# aif2 register map
Vendor: Texas Instruments
Registers are 32-bit, read-write, no defined reset value unless marked. A register's access mark holds for its fields unless they carry their own. Offsets are as the file gives them; [hi:lo] are bit positions; {n}, {i} and the like mark numbered series; 'fields as' and 'values as' point back to an identical list.

## AIF2 (part 2 of 3)
0xE010 AD_Ingress_Scheduler_EOP_Counter_Register ro — This register provides a count of the EOPs sent to the CPPI DMA Controller for activity monitoring.
  [23:0] eop_cnt — Wrapping count of EOPs sent to the CPPI DMA COntroller.
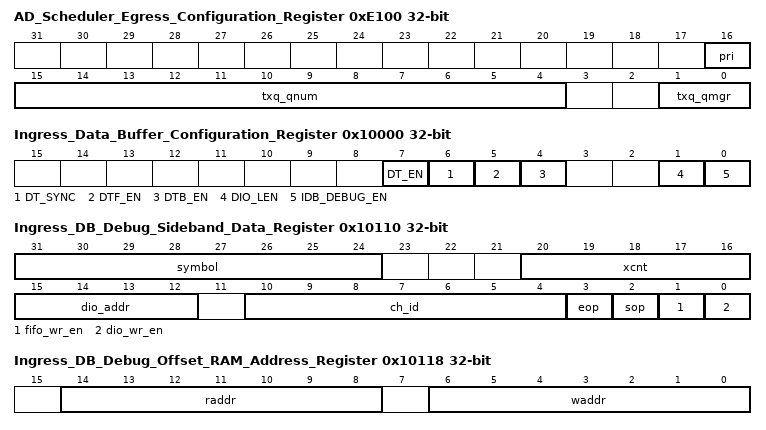
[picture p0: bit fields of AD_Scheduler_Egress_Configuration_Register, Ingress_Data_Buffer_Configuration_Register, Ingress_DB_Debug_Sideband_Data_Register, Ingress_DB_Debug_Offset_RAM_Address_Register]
0xE100 AD_Scheduler_Egress_Configuration_Register
  [16] pri — This field controls the Egress Scheduler aribitration priority
  [15:4] txq_qnum — Base egress queue number for AIF2. Channel id of each packet 127-0 added to this base value to generate egress queue number sent to CDMA Scheduling Interface. 0xF80 to 0x000
  [1:0] txq_qmgr — Queue manager number sent to CDMA Scheduling Interface for all egress transactions 0x3 to 0x0
0xE104 AD_Scheduler_Egress_Global_Enable_Set_Register wo — Set Global Enable for AD Egress Scheduler
  [31:0] DONT_CARE — A write of any value to this register sets the global enable for the AD Egress Scheduler
0xE108 AD_Scheduler_Egress_Global_Enable_Clear wo — Clear Global Enable for AD Egress Scheduler
  [31:0] DONT_CARE — A write of any value to this register clears the global enable for the AD Egress Scheduler
0xE10C AD_Scheduler_Egress_Global_Enable_Status ro — Read Only status of AD Egress Scheduler global enable state.
  [0] ENABLE — 0x1: AD Egress Scheduler_ON 0x0:AD Egress Scheduler OFF
0x10000 Ingress_Data_Buffer_Configuration_Register
  [7] DT_EN — Data Trace Enable
  [6] DT_SYNC — Data Trace Sync Enable. When data trace capture is synchronized to the frame boundary, the least significant byte of the first quad-word is always the first byte of the frame regardless of whether the first byte was the even or odd byte
  [5] DTF_EN — Trace Framing Data Capture Enable
  [4] DTB_EN — Trace Data Capture Enable
  [1] DIO_LEN — DirectIO buffer length
  [0] IDB_DEBUG_EN — Enable Ingress DB debug mode
0x10004 IDB_Global_Enable_Set_Register wo — Set Global Enable for Ingress DB
  [31:0] DONT_CARE — A write of any value to this register sets the global enable for the Ingress DB
0x10008 IDB_Global_Enable_Clear_Register wo — Clear Global Enable for Ingress DB
  [31:0] DONT_CARE — A write of any value to this register clears the global enable for the Ingress DB
0x1000C IDB_Global_Enable_Status_Register ro — Read Only status of Ingress DB global enable state.
  [0] ENABLE — 0x1: Ingress DB_ON 0x0:Ingress DB OFF
0x10010 Ingress_Data_Buffer_Channel_Enable_Register — (1 of 4, stride 4)
  [31:0] EN — Each bit is an enable for 1 of 32 contiguous Ingress data buffer channels
{0x10100+4i} Ingress_DB_Debug_Data_Register_{i} (i=0..3)
  [31:0] DATA — Debug data written to bits {32i+31}:{32i} of Ingress DB RAM
0x10110 Ingress_DB_Debug_Sideband_Data_Register — This register provides sideband data that is written into the Ingress DB RAM during debug.
  [31:24] symbol — AxC symbol number inserted as part of protocol specific data (0x00
  [20:16] xcnt — Transfer Byte Count: Indicates how many valid bytes are transferred in the current data phase.
  [15:12] dio_addr — Address within a DirectIO Circular Buffer. Each address contains a quad-word and 16 locations support up to 256 byte circular buffers.
  [10:4] ch_id — DMA channel number 127-0
  [3] eop — End of packet
  [2] sop — Start of packet
  [1] fifo_wr_en — FIFO Buffer Write Enable
  [0] dio_wr_en — DirectIO Buffer Write Enable
0x10114 Ingress_DB_Debug_DB_Write wo — A write of any value to this register writes the data in the following registers into the Ingress DB RAM and sideband RAMS: DB_IDB_DEBUG_D0, DB_IDB_DEBUG_D1, DB_IDB_DEBUG_D2, DB_IDB_DEBUG_D3, DB_IDB_DEBUG_SBDN0, DB_IDB_DEBUG_SBDN1
  [31:0] DONT_CARE — A write of any value to this register writes the data in the following registers into the Ingress DB and sideband RAMS: DB_IDB_DEBUG_D0, DB_IDB_DEBUG_D1, DB_IDB_DEBUG_D2, DB_IDB_DEBUG_D3, DB_IDB_DEBUG_SBDN0, DB_IDB_DEBUG_SBDN1
0x10118 Ingress_DB_Debug_Offset_RAM_Address_Register — This register provides the addresses to access the Ingress read and write offset RAMs for debug.
  [14:8] raddr — Address used to access read offset RAM
  [6:0] waddr — Address used to access write offset RAM
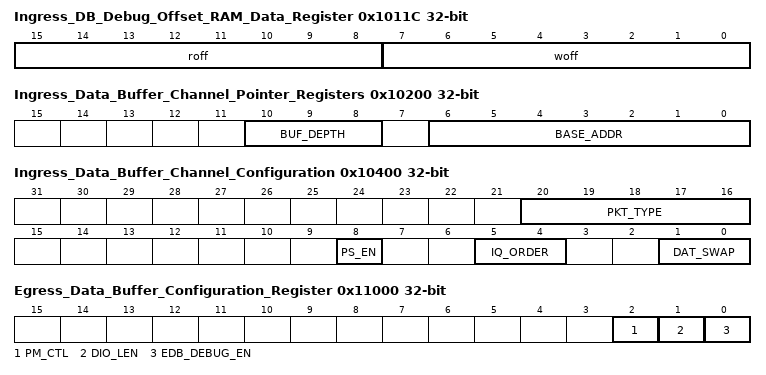
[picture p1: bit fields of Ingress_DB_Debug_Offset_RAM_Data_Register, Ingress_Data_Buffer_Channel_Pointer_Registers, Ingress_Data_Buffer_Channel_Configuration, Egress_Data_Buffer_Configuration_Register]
0x1011C Ingress_DB_Debug_Offset_RAM_Data_Register ro — This register contains the offset value read from the Ingress read and write offset RAMs for debug.
  [15:8] roff — Read offset value at address in DB_IDB_DEBUG_OFS.RADDR
  [7:0] woff — Write Offset Value at address in DB_IDB_DEBUG_OFS.WADDR
0x10200 Ingress_Data_Buffer_Channel_Pointer_Registers — (1 of 128, stride 4)
  [10:8] BUF_DEPTH — Depth of FIFO Buffer in number of quad-words (ignored for DirectIO circular buffers)
  [6:0] BASE_ADDR — Starting address of per-channel FIFO or DirectIO buffer.
0x10400 Ingress_Data_Buffer_Channel_Configuration — (1 of 128, stride 4)
  [20:16] PKT_TYPE — Programmable packet type that is inserted into pkt_type field in CPPI Info Word 0.
  [8] PS_EN — Protocol Specific Data Enable.
  [5:4] IQ_ORDER — IQ swapping scheme.
  [1:0] DAT_SWAP — Big endian swapping control.
0x10600 Ingress_Data_Buffer_Channel_Empty_Register ro — (1 of 4, stride 4)
  [31:0] EMPTY — Each bit is a buffer empty bit for 1 of 32 contiguous Ingress data buffer channels
0x11000 Egress_Data_Buffer_Configuration_Register
  [2] PM_CTL — PM Token Control
  [1] DIO_LEN — DirectIO buffer length
  [0] EDB_DEBUG_EN — Enable Egress DB debug mode
0x11004 EDB_Global_Enable_Set_Register wo — Set Global Enable for Egress DB
  [31:0] DONT_CARE — A write of any value to this register sets the global enable for the Egress DB
0x11008 EDB_Global_Enable_Clear_Register wo — Clear Global Enable for Egress DB
  [31:0] DONT_CARE — A write of any value to this register clears the global enable for the Egress DB
0x1100C EDB_Global_Enable_Status_Register ro — Read Only status of Egress DB global enable state.
  [0] ENABLE — 0x1: Egress DB_ON 0x0:Egress DB OFF
0x11010 Egress_Data_Buffer_Channel_Enable_Register — (1 of 4, stride 4)
  [31:0] EN — Each bit is an enable for 1 of 32 contiguous Egress data buffer channels
{0x11100+4i} Egress_DB_Debug_Data_Register_{i} ro (i=0..3)
  [31:0] DATA — Debug data read from bits {32i+31}:{32i} of Egress DB RAM
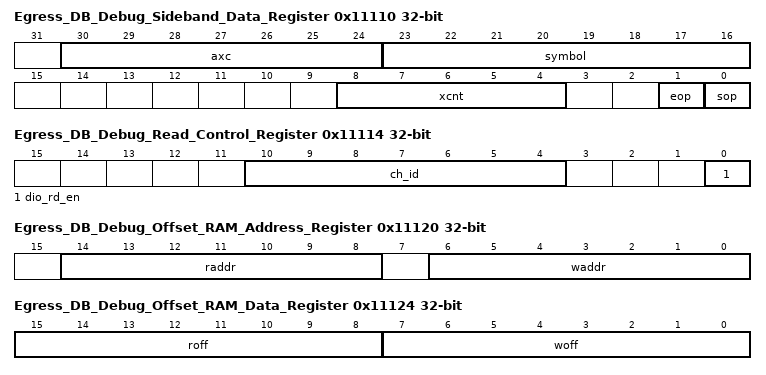
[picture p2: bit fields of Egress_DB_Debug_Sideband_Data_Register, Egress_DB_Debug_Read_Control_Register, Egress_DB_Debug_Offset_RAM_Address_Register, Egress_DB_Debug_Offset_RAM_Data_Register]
0x11110 Egress_DB_Debug_Sideband_Data_Register ro — This register provides part of the sideband data that is written into the Egress DB RAM during debug.
  [30:24] axc — AxC number from protocol specific data. Not applicable for DirectIO. For OBSAI GSM BB hopping AxC, bits \[6:0\] of OBSAI address
  [23:16] symbol — SYMBOL NUMBER from protocol specific data. Not applicable for DirectIO. For OBSAI GSM BB hopping AxC, bits \[12:7\] of OBSAI address in symbol\[5:0\]
  [8:4] xcnt — Transfer Byte Count: Indicates how many bytes in DB_EDB_DEBUG_D0, DB_EDB_DEBUG_D1, DB_EDB_DEBUG_D2, DB_EDB_DEBUG_D3 and DB_EDB_DEBUG_SBND are valid.
  [1] eop — End of packet
  [0] sop — Start of packet
0x11114 Egress_DB_Debug_Read_Control_Register — This register provides the controls necessary to read the Egress DB RAM during debug.
  [10:4] ch_id — Egress Data Buffer channel number 127-0; Also used as token channel number when DB_EDB_DEBUG_WR_TOK written
  [0] dio_rd_en — DirectIO Buffer Read Enable
0x1111C Egress_DB_Debug_DB_Read_Register wo — A write of any value to this register initiates a read to the Egress DB data and sideband RAMs and writes the contents into the following registers: DB_EDB_DEBUG_D0, DB_EDB_DEBUG_D1, DB_EDB_DEBUG_D2, DB_EDB_DEBUG_D3, DB_EDB_DEBUG_SBND
  [31:0] DONT_CARE
0x11120 Egress_DB_Debug_Offset_RAM_Address_Register — This register provides the addresses to access the Egress read and write offset RAMs for debug.
  fields as Ingress_DB_Debug_Offset_RAM_Address_Register
0x11124 Egress_DB_Debug_Offset_RAM_Data_Register ro — This register contains the offset value read from the Egress read and write offset RAMs for debug.
  [15:8] roff — Read offset value at address in DB_EDB_DEBUG_OFS.RADDR
  [7:0] woff — Write Offset Value at address in DB_EDB_DEBUG_OFS.WADDR
0x11128 Egress_DB_Debug_Write_Token_Register wo — A write of any value to this register results in a token with the value loaded into DB_EDB_DEBUG_RD_CNTL.CH_ID being issued to the AxC Token FIFO
  [31:0] DONT_CARE
0x1112C Egress_DB_EOP_Counter_Register ro — This register provides a count of the Egress EOPs received from the CPPI DMA Controller for activity monitoring.
  [23:0] eop_cnt — Wrapping count of EOPs received from the CPPI DMA COntroller.
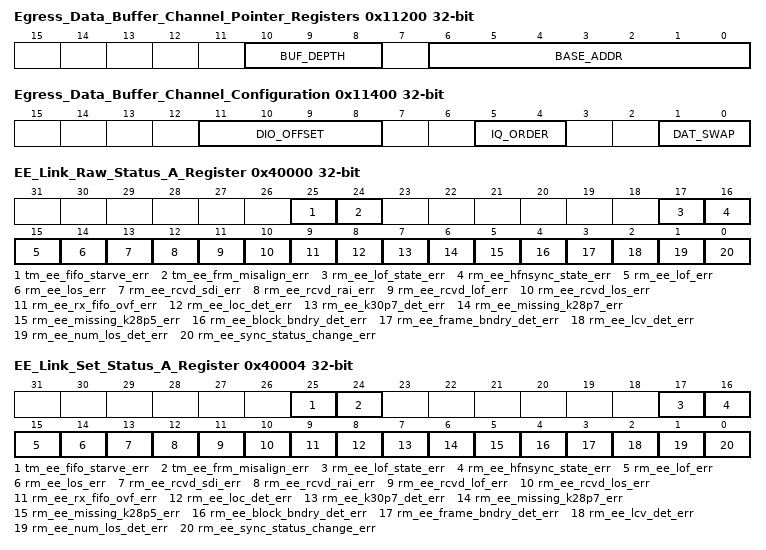
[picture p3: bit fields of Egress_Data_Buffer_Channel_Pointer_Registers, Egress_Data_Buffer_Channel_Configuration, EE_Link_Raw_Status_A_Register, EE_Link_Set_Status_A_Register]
0x11200 Egress_Data_Buffer_Channel_Pointer_Registers — (1 of 128, stride 4)
  fields as Ingress_Data_Buffer_Channel_Pointer_Registers
0x11400 Egress_Data_Buffer_Channel_Configuration — (1 of 128, stride 4)
  [11:8] DIO_OFFSET — Address offset of SOP for DIO channels
  [5:4] IQ_ORDER — IQ swapping scheme.
  [1:0] DAT_SWAP — Big endian swapping control.
0x40000 EE_Link_Raw_Status_A_Register ro — (1 of 6, stride 128)
  [25] tm_ee_fifo_starve_err — TM FIFO Strave Error.
  [24] tm_ee_frm_misalign_err — TM Frame Misalign Error.
  [17] rm_ee_lof_state_err — RM LOF State Error.
  [16] rm_ee_hfnsync_state_err — RM Hyperframe State Error.
  [15] rm_ee_lof_err — RM LOF Error
  [14] rm_ee_los_err — RM LOS Error.
  [13] rm_ee_rcvd_sdi_err — RM Received SDI Error.
  [12] rm_ee_rcvd_rai_err — RM Received RAI Error.
  [11] rm_ee_rcvd_lof_err — RM Received LOF Error.
  [10] rm_ee_rcvd_los_err — RM Received LOS Error.
  [9] rm_ee_rx_fifo_ovf_err — RM RX FIFO Overflow Error.
  [8] rm_ee_loc_det_err — RM LOC Detect Error.
  [7] rm_ee_k30p7_det_err — RM K30p7 Detect Error.
  [6] rm_ee_missing_k28p7_err — RM Missing K28p7 Error.
  [5] rm_ee_missing_k28p5_err — RM Missing K28p5 Error.
  [4] rm_ee_block_bndry_det_err — RM Block Boundary Detect Error.
  [3] rm_ee_frame_bndry_det_err — RM Frame Boundary Detect Error.
  [2] rm_ee_lcv_det_err — RM LCV Detect Error.
  [1] rm_ee_num_los_det_err — RM Num Loss Detect Error.
  [0] rm_ee_sync_status_change_err — RM Sync Status Change Error.
0x40004 EE_Link_Set_Status_A_Register wo — (1 of 6, stride 128)
  [25] tm_ee_fifo_starve_err — TM FIFO Strave Error Set.
  [24] tm_ee_frm_misalign_err — TM Frame Misalign Error Set.
  [17] rm_ee_lof_state_err — RM LOF State Error Set.
  [16] rm_ee_hfnsync_state_err — RM Hyperframe State Error Set.
  [15] rm_ee_lof_err — RM LOF Error Set.
  [14] rm_ee_los_err — RM LOS Error Set.
  [13] rm_ee_rcvd_sdi_err — RM Received SDI Error Set.
  [12] rm_ee_rcvd_rai_err — RM Received RAI Error Set.
  [11] rm_ee_rcvd_lof_err — RM Received LOF Error Set.
  [10] rm_ee_rcvd_los_err — RM Received LOS Error Set.
  [9] rm_ee_rx_fifo_ovf_err — RM RX FIFO Overflow Error Set.
  [8] rm_ee_loc_det_err — RM LOC Detect Error Set.
  [7] rm_ee_k30p7_det_err — RM K30p7 Detect Error Set.
  [6] rm_ee_missing_k28p7_err — RM Missing K28p7 Error Set.
  [5] rm_ee_missing_k28p5_err — RM Missing K28p5 Error Set.
  [4] rm_ee_block_bndry_det_err — RM Block Boundary Detect Error Set.
  [3] rm_ee_frame_bndry_det_err — RM Frame Boundary Detect Error Set.
  [2] rm_ee_lcv_det_err — RM LCV Detect Error Set.
  [1] rm_ee_num_los_det_err — RM Num Loss Detect Error Set.
  [0] rm_ee_sync_status_change_err — RM Sync Status Change Error Set.
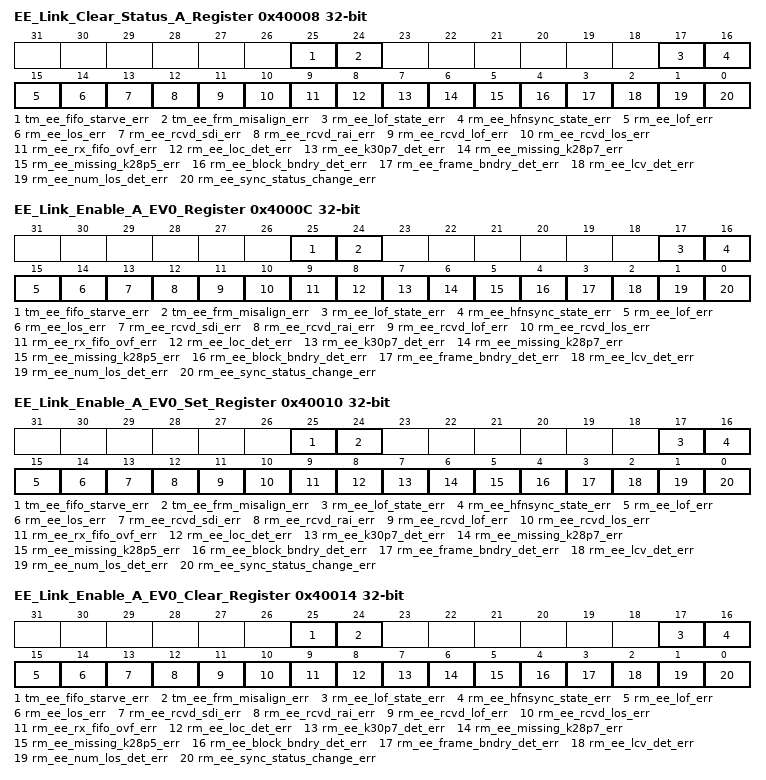
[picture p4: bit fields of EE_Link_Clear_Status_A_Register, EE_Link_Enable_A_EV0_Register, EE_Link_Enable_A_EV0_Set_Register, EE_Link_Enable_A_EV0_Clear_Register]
0x40008 EE_Link_Clear_Status_A_Register wo — (1 of 6, stride 128)
  [25] tm_ee_fifo_starve_err — TM FIFO Strave Error Clear.
  [24] tm_ee_frm_misalign_err — TM Frame Misalign Error Clear.
  [17] rm_ee_lof_state_err — RM LOF State Error Clear.
  [16] rm_ee_hfnsync_state_err — RM Hyperframe State Error Clear.
  [15] rm_ee_lof_err — RM LOF Error Clear.
  [14] rm_ee_los_err — RM LOS Error Clear.
  [13] rm_ee_rcvd_sdi_err — RM Received SDI Error Clear.
  [12] rm_ee_rcvd_rai_err — RM Received RAI Error Clear.
  [11] rm_ee_rcvd_lof_err — RM Received LOF Error Clear.
  [10] rm_ee_rcvd_los_err — RM Received LOS Error Clear.
  [9] rm_ee_rx_fifo_ovf_err — RM RX FIFO Overflow Error Clear.
  [8] rm_ee_loc_det_err — RM LOC Detect Error Clear.
  [7] rm_ee_k30p7_det_err — RM K30p7 Detect Error Clear.
  [6] rm_ee_missing_k28p7_err — RM Missing K28p7 Error Clear.
  [5] rm_ee_missing_k28p5_err — RM Missing K28p5 Error Clear.
  [4] rm_ee_block_bndry_det_err — RM Block Boundary Detect Error Clear.
  [3] rm_ee_frame_bndry_det_err — RM Frame Boundary Detect Error Clear.
  [2] rm_ee_lcv_det_err — RM LCV Detect Error Clear.
  [1] rm_ee_num_los_det_err — RM Num Loss Detect Erro Clear.
  [0] rm_ee_sync_status_change_err — RM Sync Status Change Error Clear.
0x4000C EE_Link_Enable_A_EV0_Register ro — (1 of 6, stride 128)
  [25] tm_ee_fifo_starve_err — TM FIFO Strave Error Enable.
  [24] tm_ee_frm_misalign_err — TM Frame Misalign Error Enable.
  [17] rm_ee_lof_state_err — RM LOF State Error Enable.
  [16] rm_ee_hfnsync_state_err — RM Hyperframe State Error Enable.
  [15] rm_ee_lof_err — RM LOF Error Enable.
  [14] rm_ee_los_err — RM LOS Error Enable.
  [13] rm_ee_rcvd_sdi_err — RM Received SDI Error Enable.
  [12] rm_ee_rcvd_rai_err — RM Received RAI Error Enable.
  [11] rm_ee_rcvd_lof_err — RM Received LOF Error Enable.
  [10] rm_ee_rcvd_los_err — RM Received LOS Error Enable.
  [9] rm_ee_rx_fifo_ovf_err — RM RX FIFO Overflow Error Enable.
  [8] rm_ee_loc_det_err — RM LOC Detect Error Enable.
  [7] rm_ee_k30p7_det_err — RM K30p7 Detect Error Enable.
  [6] rm_ee_missing_k28p7_err — RM Missing K28p7 Error Enable.
  [5] rm_ee_missing_k28p5_err — RM Missing K28p5 Error Enable.
  [4] rm_ee_block_bndry_det_err — RM Block Boundary Detect Error Enable.
  [3] rm_ee_frame_bndry_det_err — RM Frame Boundary Detect Error Enable.
  [2] rm_ee_lcv_det_err — RM LCV Detect Error Enable.
  [1] rm_ee_num_los_det_err — RM Num Loss Detect ErroSet.
  [0] rm_ee_sync_status_change_err — RM Sync Status Change Error Enable.
0x40010 EE_Link_Enable_A_EV0_Set_Register wo — (1 of 6, stride 128)
  [25] tm_ee_fifo_starve_err — TM FIFO Strave Error Enable Set.
  [24] tm_ee_frm_misalign_err — TM Frame Misalign Error Enable Set.
  [17] rm_ee_lof_state_err — RM LOF State Error Enable Set.
  [16] rm_ee_hfnsync_state_err — RM Hyperframe State Error Enable Set.
  [15] rm_ee_lof_err — RM LOF Error Enable Set.
  [14] rm_ee_los_err — RM LOS Error Enable Set.
  [13] rm_ee_rcvd_sdi_err — RM Received SDI Error Enable Set.
  [12] rm_ee_rcvd_rai_err — RM Received RAI Error Enable Set.
  [11] rm_ee_rcvd_lof_err — RM Received LOF Error Enable Set.
  [10] rm_ee_rcvd_los_err — RM Received LOS Error Enable Set.
  [9] rm_ee_rx_fifo_ovf_err — RM RX FIFO Overflow Error Enable Set.
  [8] rm_ee_loc_det_err — RM LOC Detect Error Enable Set.
  [7] rm_ee_k30p7_det_err — RM K30p7 Detect Error Enable Set.
  [6] rm_ee_missing_k28p7_err — RM Missing K28p7 Error Enable Set.
  [5] rm_ee_missing_k28p5_err — RM Missing K28p5 Error Enable Set.
  [4] rm_ee_block_bndry_det_err — RM Block Boundary Detect Error Enable Set.
  [3] rm_ee_frame_bndry_det_err — RM Frame Boundary Detect Error Enable Set.
  [2] rm_ee_lcv_det_err — RM LCV Detect Error Enable Set.
  [1] rm_ee_num_los_det_err — RM Num Loss Detect ErroSet.
  [0] rm_ee_sync_status_change_err — RM Sync Status Change Error Enable Set.
0x40014 EE_Link_Enable_A_EV0_Clear_Register wo — (1 of 6, stride 128)
  [25] tm_ee_fifo_starve_err — TM FIFO Strave Error Enable Clear.
  [24] tm_ee_frm_misalign_err — TM Frame Misalign Error Enable Clear.
  [17] rm_ee_lof_state_err — RM LOF State Error Enable Clear.
  [16] rm_ee_hfnsync_state_err — RM Hyperframe State Error Enable Clear.
  [15] rm_ee_lof_err — RM LOF Error Enable Clear.
  [14] rm_ee_los_err — RM LOS Error Enable Clear.
  [13] rm_ee_rcvd_sdi_err — RM Received SDI Error Enable Clear.
  [12] rm_ee_rcvd_rai_err — RM Received RAI Error Enable Clear.
  [11] rm_ee_rcvd_lof_err — RM Received LOF Error Enable Clear.
  [10] rm_ee_rcvd_los_err — RM Received LOS Error Enable Clear.
  [9] rm_ee_rx_fifo_ovf_err — RM RX FIFO Overflow Error Enable Clear.
  [8] rm_ee_loc_det_err — RM LOC Detect Error Enable Clear.
  [7] rm_ee_k30p7_det_err — RM K30p7 Detect Error Enable Clear.
  [6] rm_ee_missing_k28p7_err — RM Missing K28p7 Error Enable Clear.
  [5] rm_ee_missing_k28p5_err — RM Missing K28p5 Error Enable Clear.
  [4] rm_ee_block_bndry_det_err — RM Block Boundary Detect Error Enable Clear.
  [3] rm_ee_frame_bndry_det_err — RM Frame Boundary Detect Error Enable Clear.
  [2] rm_ee_lcv_det_err — RM LCV Detect Error Enable Clear.
  [1] rm_ee_num_los_det_err — RM Num Loss Detect ErroSet.
  [0] rm_ee_sync_status_change_err — RM Sync Status Change Error Enable Clear.
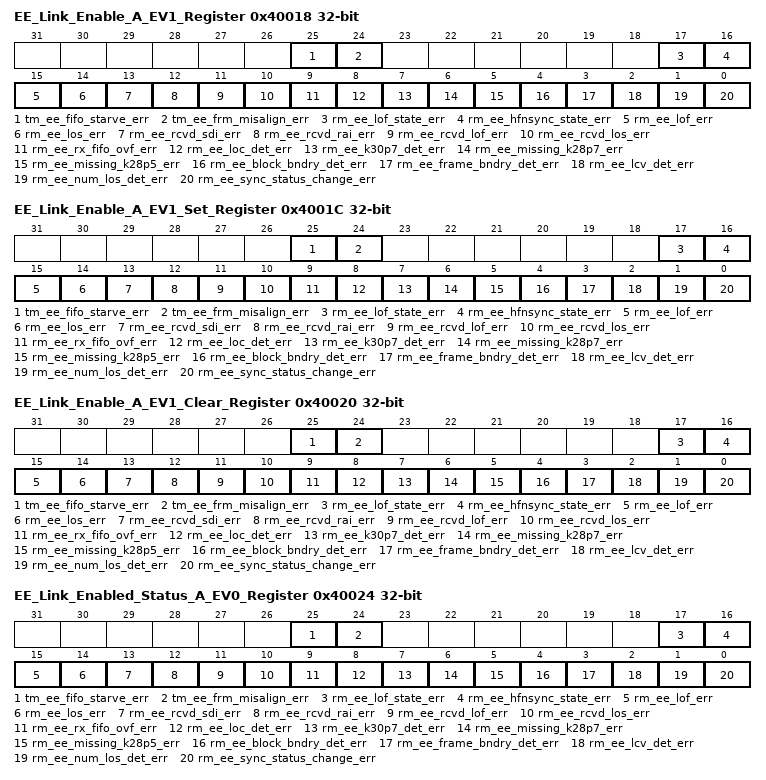
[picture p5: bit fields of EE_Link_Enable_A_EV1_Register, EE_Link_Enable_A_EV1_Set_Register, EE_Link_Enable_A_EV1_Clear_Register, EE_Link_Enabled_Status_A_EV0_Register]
0x40018 EE_Link_Enable_A_EV1_Register ro — (1 of 6, stride 128)
  fields as EE_Link_Enable_A_EV0_Register
0x4001C EE_Link_Enable_A_EV1_Set_Register wo — (1 of 6, stride 128)
  fields as EE_Link_Enable_A_EV0_Set_Register
0x40020 EE_Link_Enable_A_EV1_Clear_Register wo — (1 of 6, stride 128)
  fields as EE_Link_Enable_A_EV0_Clear_Register
0x40024 EE_Link_Enabled_Status_A_EV0_Register ro — (1 of 6, stride 128)
  [25] tm_ee_fifo_starve_err — TM FIFO Strave Error Enabled.
  [24] tm_ee_frm_misalign_err — TM Frame Misalign Error Enabled.
  [17] rm_ee_lof_state_err — RM LOF State Error Enabled.
  [16] rm_ee_hfnsync_state_err — RM Hyperframe State Error Enabled.
  [15] rm_ee_lof_err — RM LOF Error
  [14] rm_ee_los_err — RM LOS Error Enabled.
  [13] rm_ee_rcvd_sdi_err — RM Received SDI Error Enabled.
  [12] rm_ee_rcvd_rai_err — RM Received RAI Error Enabled.
  [11] rm_ee_rcvd_lof_err — RM Received LOF Error Enabled.
  [10] rm_ee_rcvd_los_err — RM Received LOS Error Enabled.
  [9] rm_ee_rx_fifo_ovf_err — RM RX FIFO Overflow Error Enabled.
  [8] rm_ee_loc_det_err — RM LOC Detect Error Enabled.
  [7] rm_ee_k30p7_det_err — RM K30p7 Detect Error Enabled.
  [6] rm_ee_missing_k28p7_err — RM Missing K28p7 Error Enabled.
  [5] rm_ee_missing_k28p5_err — RM Missing K28p5 Error Enabled.
  [4] rm_ee_block_bndry_det_err — RM Block Boundary Detect Error Enabled.
  [3] rm_ee_frame_bndry_det_err — RM Frame Boundary Detect Error Enabled.
  [2] rm_ee_lcv_det_err — RM LCV Detect Error Enabled.
  [1] rm_ee_num_los_det_err — RM Num Loss Detect Error Enabled.
  [0] rm_ee_sync_status_change_err — RM Sync Status Change Error Enabled.
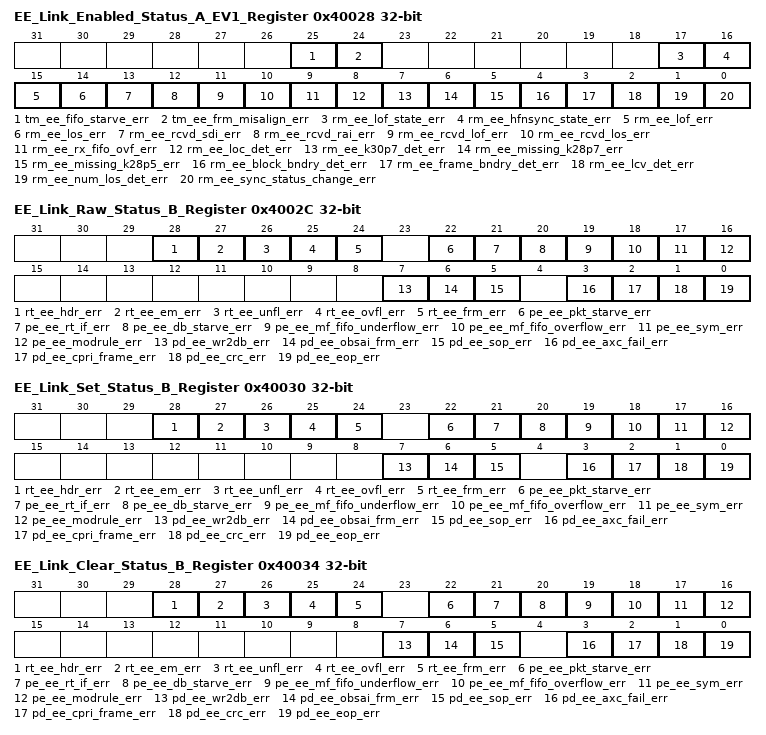
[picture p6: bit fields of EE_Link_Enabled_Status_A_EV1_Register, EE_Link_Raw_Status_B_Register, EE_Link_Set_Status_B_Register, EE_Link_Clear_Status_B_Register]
0x40028 EE_Link_Enabled_Status_A_EV1_Register ro — (1 of 6, stride 128)
  fields as EE_Link_Enabled_Status_A_EV0_Register
0x4002C EE_Link_Raw_Status_B_Register ro — (1 of 6, stride 128)
  [28] rt_ee_hdr_err — RT HDR Error.
  [27] rt_ee_em_err — RT EM Error.
  [26] rt_ee_unfl_err — RT Underflow Error.
  [25] rt_ee_ovfl_err — RT Overflow Error.
  [24] rt_ee_frm_err — RT Frame Error.
  [22] pe_ee_pkt_starve_err — PE packet starve Error.
  [21] pe_ee_rt_if_err — PE RT IF Error.
  [20] pe_ee_db_starve_err — PE DB starvation Error.
  [19] pe_ee_mf_fifo_underflow_err — PE MF fifo underflow Error.
  [18] pe_ee_mf_fifo_overflow_err — PE MF fifo overflow Error.
  [17] pe_ee_sym_err — PE symbol Error.
  [16] pe_ee_modrule_err — PE Mod rule Error.
  [7] pd_ee_wr2db_err — PD Write to DB Error.
  [6] pd_ee_obsai_frm_err — PD OBSAI Frame Error.
  [5] pd_ee_sop_err — PD SOP Error.
  [3] pd_ee_axc_fail_err — PD AXC Fail Error.
  [2] pd_ee_cpri_frame_err — PD CPRI Frame Error.
  [1] pd_ee_crc_err — PD CRC Error.
  [0] pd_ee_eop_err — PD EOP Error.
0x40030 EE_Link_Set_Status_B_Register wo — (1 of 6, stride 128)
  [28] rt_ee_hdr_err — RT HDR Error Set.
  [27] rt_ee_em_err — RT EM Error Set.
  [26] rt_ee_unfl_err — RT Underflow Error Set.
  [25] rt_ee_ovfl_err — RT Overflow Error Set.
  [24] rt_ee_frm_err — RT Frame Error Set.
  [22] pe_ee_pkt_starve_err — PE packet starve Error Set.
  [21] pe_ee_rt_if_err — PE RT IF Error Set.
  [20] pe_ee_db_starve_err — PE DB starvation Error Set.
  [19] pe_ee_mf_fifo_underflow_err — PE MF fifo underflow Error Set.
  [18] pe_ee_mf_fifo_overflow_err — PE MF fifo overflow Error Set.
  [17] pe_ee_sym_err — PE symbol Error Set.
  [16] pe_ee_modrule_err — PE Mod rule Error Set.
  [7] pd_ee_wr2db_err — PD Write to DB Error Set.
  [6] pd_ee_obsai_frm_err — PD OBSAI Frame Error Set.
  [5] pd_ee_sop_err — PD SOP Error Set.
  [3] pd_ee_axc_fail_err — PD AXC Fail Error Set.
  [2] pd_ee_cpri_frame_err — PD CPRI Frame Error Set.
  [1] pd_ee_crc_err — PD CRC Error Set.
  [0] pd_ee_eop_err — PD EOP Error Set.
0x40034 EE_Link_Clear_Status_B_Register wo — (1 of 6, stride 128)
  [28] rt_ee_hdr_err — RT HDR Error Clear.
  [27] rt_ee_em_err — RT EM Error Clear.
  [26] rt_ee_unfl_err — RT Underflow Error Clear.
  [25] rt_ee_ovfl_err — RT Overflow Error Clear.
  [24] rt_ee_frm_err — RT Frame Error Clear.
  [22] pe_ee_pkt_starve_err — PE packet starve Error Clear.
  [21] pe_ee_rt_if_err — PE RT IF Error Clear.
  [20] pe_ee_db_starve_err — PE DB starvation Error Clear.
  [19] pe_ee_mf_fifo_underflow_err — PE MF fifo underflow Error Clear.
  [18] pe_ee_mf_fifo_overflow_err — PE MF fifo overflow Error Clear.
  [17] pe_ee_sym_err — PE symbol Error Clear.
  [16] pe_ee_modrule_err — PE Mod rule Error Clear.
  [7] pd_ee_wr2db_err — PD Write to DB Error Clear.
  [6] pd_ee_obsai_frm_err — PD OBSAI Frame Error Clear.
  [5] pd_ee_sop_err — PD SOP Error Clear.
  [3] pd_ee_axc_fail_err — PD AXC Fail Error Clear.
  [2] pd_ee_cpri_frame_err — PD CPRI Frame Error Clear.
  [1] pd_ee_crc_err — PD CRC Error Clear.
  [0] pd_ee_eop_err — PD EOP Error Clear.
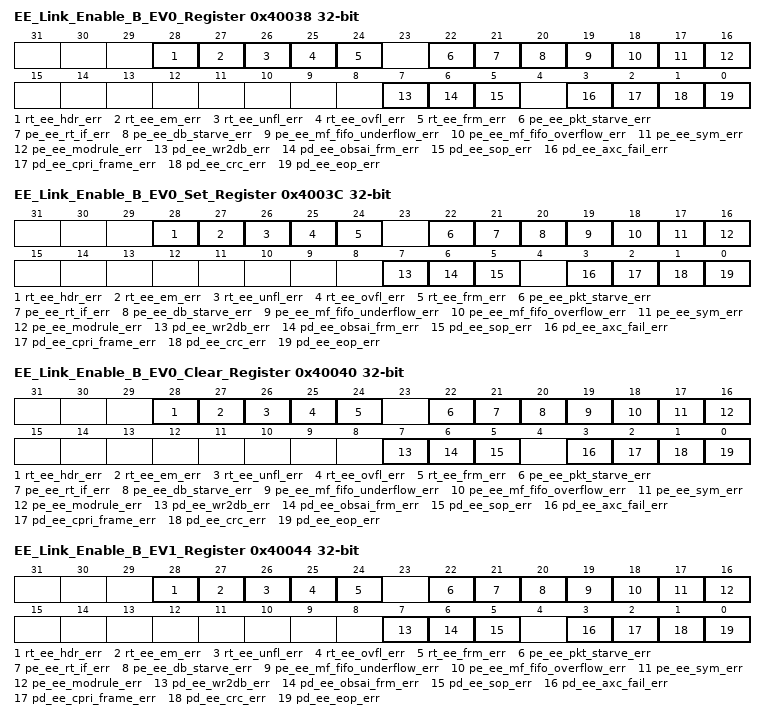
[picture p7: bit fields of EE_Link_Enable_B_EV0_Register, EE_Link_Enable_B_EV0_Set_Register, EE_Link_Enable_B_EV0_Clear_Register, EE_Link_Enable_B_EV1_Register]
0x40038 EE_Link_Enable_B_EV0_Register ro — (1 of 6, stride 128)
  [28] rt_ee_hdr_err — RT HDR Error Enable.
  [27] rt_ee_em_err — RT EM Error Enable.
  [26] rt_ee_unfl_err — RT Underflow Error Enable.
  [25] rt_ee_ovfl_err — RT Overflow Error Enable.
  [24] rt_ee_frm_err — RT Frame Error Enable.
  [22] pe_ee_pkt_starve_err — PE packet starve Error Enable.
  [21] pe_ee_rt_if_err — PE RT IF Error Enable.
  [20] pe_ee_db_starve_err — PE DB starvation Error Enable.
  [19] pe_ee_mf_fifo_underflow_err — PE MF fifo underflow Error Enable.
  [18] pe_ee_mf_fifo_overflow_err — PE MF fifo overflow Error Enable.
  [17] pe_ee_sym_err — PE symbol Error Enable.
  [16] pe_ee_modrule_err — PE Mod rule Error Enable.
  [7] pd_ee_wr2db_err — PD READ to DB Error Enable.
  [6] pd_ee_obsai_frm_err — PD OBSAI Frame Error Enable.
  [5] pd_ee_sop_err — PD SOP Error Enable.
  [3] pd_ee_axc_fail_err — PD AXC Fail Error Enable.
  [2] pd_ee_cpri_frame_err — PD CPRI Frame Error Enable.
  [1] pd_ee_crc_err — PD CRC Error Enable.
  [0] pd_ee_eop_err — PD EOP Error Enable.
0x4003C EE_Link_Enable_B_EV0_Set_Register wo — (1 of 6, stride 128)
  [28] rt_ee_hdr_err — RT HDR Error Enable Set.
  [27] rt_ee_em_err — RT EM Error Enable Set.
  [26] rt_ee_unfl_err — RT Underflow Error Enable Set.
  [25] rt_ee_ovfl_err — RT Overflow Error Enable Set.
  [24] rt_ee_frm_err — RT Frame Error Enable Set.
  [22] pe_ee_pkt_starve_err — PE packet starve Error Enable Set.
  [21] pe_ee_rt_if_err — PE RT IF Error Enable Set.
  [20] pe_ee_db_starve_err — PE DB starvation Error Enable Set.
  [19] pe_ee_mf_fifo_underflow_err — PE MF fifo underflow Error Enable Set.
  [18] pe_ee_mf_fifo_overflow_err — PE MF fifo overflow Error Enable Set.
  [17] pe_ee_sym_err — PE symbol Error Enable Set.
  [16] pe_ee_modrule_err — PE Mod rule Error Enable Set.
  [7] pd_ee_wr2db_err — PD Write to DB Error Enable Set.
  [6] pd_ee_obsai_frm_err — PD OBSAI Frame Error Enable Set.
  [5] pd_ee_sop_err — PD SOP Error Enable Set.
  [3] pd_ee_axc_fail_err — PD AXC Fail Error Enable Set.
  [2] pd_ee_cpri_frame_err — PD CPRI Frame Error Enable Set.
  [1] pd_ee_crc_err — PD CRC Error Enable Set.
  [0] pd_ee_eop_err — PD EOP Error Enable Set.
0x40040 EE_Link_Enable_B_EV0_Clear_Register wo — (1 of 6, stride 128)
  [28] rt_ee_hdr_err — RT HDR Error Enable Clear.
  [27] rt_ee_em_err — RT EM Error Enable Clear.
  [26] rt_ee_unfl_err — RT Underflow Error Enable Clear.
  [25] rt_ee_ovfl_err — RT Overflow Error Enable Clear.
  [24] rt_ee_frm_err — RT Frame Error Enable Clear.
  [22] pe_ee_pkt_starve_err — PE packet starve Error Enable Clear.
  [21] pe_ee_rt_if_err — PE RT IF Error Enable Clear.
  [20] pe_ee_db_starve_err — PE DB starvation Error Enable Clear.
  [19] pe_ee_mf_fifo_underflow_err — PE MF fifo underflow Error Enable Clear.
  [18] pe_ee_mf_fifo_overflow_err — PE MF fifo overflow Error Enable Clear.
  [17] pe_ee_sym_err — PE symbol Error Enable Clear.
  [16] pe_ee_modrule_err — PE Mod rule Error Enable Clear.
  [7] pd_ee_wr2db_err — PD Write to DB Error Enable Clear.
  [6] pd_ee_obsai_frm_err — PD OBSAI Frame Error Enable Clear.
  [5] pd_ee_sop_err — PD SOP Error Enable Clear.
  [3] pd_ee_axc_fail_err — PD AXC Fail Error Enable Clear.
  [2] pd_ee_cpri_frame_err — PD CPRI Frame Error Enable Clear.
  [1] pd_ee_crc_err — PD CRC Error Enable Clear.
  [0] pd_ee_eop_err — PD EOP Error Enable Clear.
0x40044 EE_Link_Enable_B_EV1_Register ro — (1 of 6, stride 128)
  fields as EE_Link_Enable_B_EV0_Register
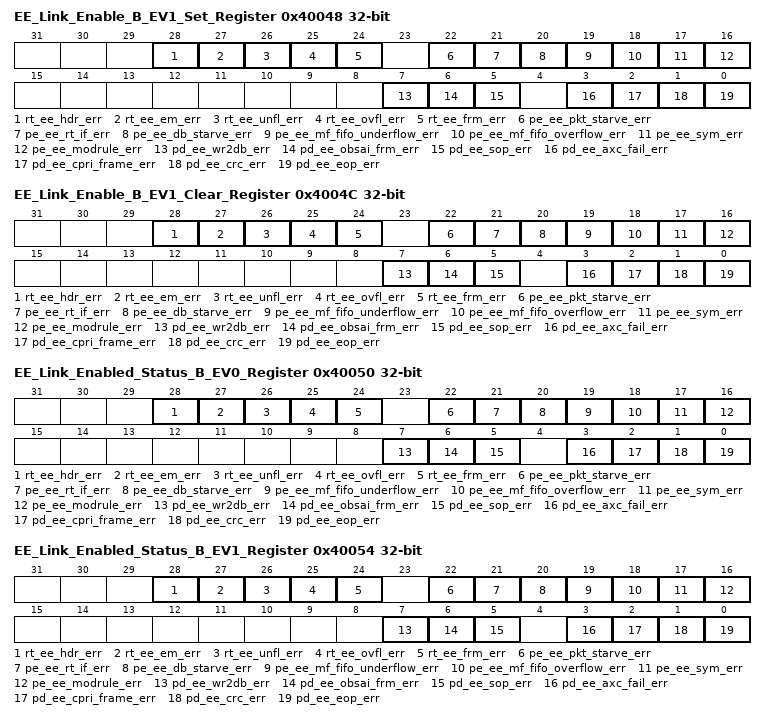
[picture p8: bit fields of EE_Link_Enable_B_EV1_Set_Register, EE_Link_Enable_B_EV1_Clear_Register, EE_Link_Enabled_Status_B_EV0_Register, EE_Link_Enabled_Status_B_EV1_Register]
0x40048 EE_Link_Enable_B_EV1_Set_Register wo — (1 of 6, stride 128)
  fields as EE_Link_Enable_B_EV0_Set_Register
0x4004C EE_Link_Enable_B_EV1_Clear_Register wo — (1 of 6, stride 128)
  fields as EE_Link_Enable_B_EV0_Clear_Register
0x40050 EE_Link_Enabled_Status_B_EV0_Register ro — (1 of 6, stride 128)
  [28] rt_ee_hdr_err — RT HDR Error Enabled.
  [27] rt_ee_em_err — RT EM Error Enabled.
  [26] rt_ee_unfl_err — RT Underflow Error Enabled.
  [25] rt_ee_ovfl_err — RT Overflow Error Enabled.
  [24] rt_ee_frm_err — RT Frame Error Enabled.
  [22] pe_ee_pkt_starve_err — PE packet starve Error Enabled.
  [21] pe_ee_rt_if_err — PE RT IF Error Enabled.
  [20] pe_ee_db_starve_err — PE DB starvation Error Enabled.
  [19] pe_ee_mf_fifo_underflow_err — PE MF fifo underflow Error Enabled.
  [18] pe_ee_mf_fifo_overflow_err — PE MF fifo overflow Error Enabled.
  [17] pe_ee_sym_err — PE symbol Error Enabled.
  [16] pe_ee_modrule_err — PE Mod rule Error Enabled.
  [7] pd_ee_wr2db_err — PD Write to DB Error Enabled.
  [6] pd_ee_obsai_frm_err — PD OBSAI Frame Error Enabled.
  [5] pd_ee_sop_err — PD SOP Error Enabled.
  [3] pd_ee_axc_fail_err — PD AXC Fail Error Enabled.
  [2] pd_ee_cpri_frame_err — PD CPRI Frame Error Enabled.
  [1] pd_ee_crc_err — PD CRC Error Enabled.
  [0] pd_ee_eop_err — PD EOP Error Enabled.
0x40054 EE_Link_Enabled_Status_B_EV1_Register ro — (1 of 6, stride 128)
  fields as EE_Link_Enabled_Status_B_EV0_Register
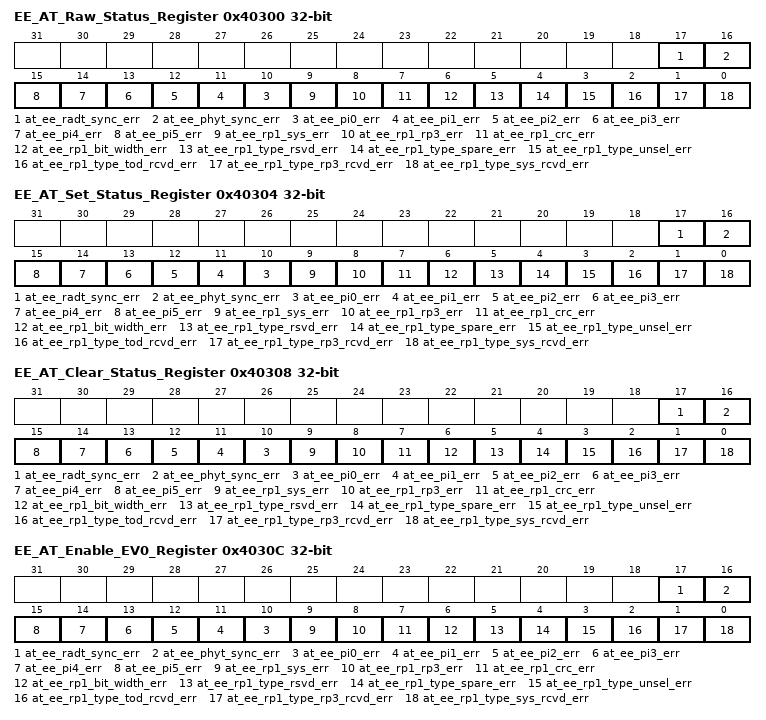
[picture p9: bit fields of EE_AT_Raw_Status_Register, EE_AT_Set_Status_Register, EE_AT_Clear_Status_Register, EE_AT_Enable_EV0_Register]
0x40300 EE_AT_Raw_Status_Register ro
  [17] at_ee_radt_sync_err — AT RADT sync input is not aligned to the RADT counter frame boundary Error.
  [16] at_ee_phyt_sync_err — AT PHYT sync input is not aligned to the PHYT counter frame boundary Error.
  [n+10] at_ee_pi{n}_err (n=0..5) — AT Link {n} PI Error.
  [9] at_ee_rp1_sys_err — AT RADT selected width Frame number does not match the received RP1 SYS frame number Error.
  [8] at_ee_rp1_rp3_err — AT PHYT selected width Frame number does not match the received RP1 RP3 frame number Error.
  [7] at_ee_rp1_crc_err — AT RP1 Type CRC Error.
  [6] at_ee_rp1_bit_width_err — AT RP1 Type Bit Width Error.
  [5] at_ee_rp1_type_rsvd_err — AT RP1 Type Reserved Error.
  [4] at_ee_rp1_type_spare_err — AT RP1 Type Spare Error.
  [3] at_ee_rp1_type_unsel_err — AT RP1 Type Unsel Error.
  [2] at_ee_rp1_type_tod_rcvd_err — AT RP1 Type TOD Receive Error.
  [1] at_ee_rp1_type_rp3_rcvd_err — AT RP1 Type RP3 Receive Error.
  [0] at_ee_rp1_type_sys_rcvd_err — AT RP1 Type SYS Receive Error.
0x40304 EE_AT_Set_Status_Register wo
  [17] at_ee_radt_sync_err — AT RADT sync input is not aligned to the RADT counter frame boundary Error Set.
  [16] at_ee_phyt_sync_err — AT PHYT sync input is not aligned to the PHYT counter frame boundary Error Set.
  [n+10] at_ee_pi{n}_err (n=0..5) — AT Link {n} PI Error Set.
  [9] at_ee_rp1_sys_err — AT RADT selected width Frame number does not match the received RP1 SYS frame number Error Set.
  [8] at_ee_rp1_rp3_err — AT PHYT selected width Frame number does not match the received RP1 RP3 frame number Error Set.
  [7] at_ee_rp1_crc_err — AT RP1 Type CRC Error Set.
  [6] at_ee_rp1_bit_width_err — AT RP1 Type Bit Width Error Set.
  [5] at_ee_rp1_type_rsvd_err — AT RP1 Type Reserved Error Set.
  [4] at_ee_rp1_type_spare_err — AT RP1 Type Spare Error Set.
  [3] at_ee_rp1_type_unsel_err — AT RP1 Type Unsel Error Set.
  [2] at_ee_rp1_type_tod_rcvd_err — AT RP1 Type TOD Receive Error Set.
  [1] at_ee_rp1_type_rp3_rcvd_err — AT RP1 Type RP3 Receive Error Set.
  [0] at_ee_rp1_type_sys_rcvd_err — AT RP1 Type SYS Receive Error Set.
0x40308 EE_AT_Clear_Status_Register wo
  [17] at_ee_radt_sync_err — AT RADT sync input is not aligned to the RADT counter frame boundary Error Clear.
  [16] at_ee_phyt_sync_err — AT PHYT sync input is not aligned to the PHYT counter frame boundary Error Clear.
  [n+10] at_ee_pi{n}_err (n=0..5) — AT Link {n} PI Error Clear.
  [9] at_ee_rp1_sys_err — AT RADT selected width Frame number does not match the received RP1 SYS frame number Error Clear.
  [8] at_ee_rp1_rp3_err — AT PHYT selected width Frame number does not match the received RP1 RP3 frame number Error Clear.
  [7] at_ee_rp1_crc_err — AT RP1 Type CRC Error Clear.
  [6] at_ee_rp1_bit_width_err — AT RP1 Type Bit Width Error Clear.
  [5] at_ee_rp1_type_rsvd_err — AT RP1 Type Reserved Error Clear.
  [4] at_ee_rp1_type_spare_err — AT RP1 Type Spare Error Clear.
  [3] at_ee_rp1_type_unsel_err — AT RP1 Type Unsel Error Clear.
  [2] at_ee_rp1_type_tod_rcvd_err — AT RP1 Type TOD Receive Error Clear.
  [1] at_ee_rp1_type_rp3_rcvd_err — AT RP1 Type RP3 Receive Error Clear.
  [0] at_ee_rp1_type_sys_rcvd_err — AT RP1 Type SYS Receive Error Clear.
0x4030C EE_AT_Enable_EV0_Register ro — EE AT Enable EVO Register
  [17] at_ee_radt_sync_err — AT RADT sync input is not aligned to the RADT counter frame boundary Error Enable.
  [16] at_ee_phyt_sync_err — AT PHYT sync input is not aligned to the PHYT counter frame boundary Error Enable.
  [n+10] at_ee_pi{n}_err (n=0..5) — AT Link {n} PI Error Enable.
  [9] at_ee_rp1_sys_err — AT RADT selected width Frame number does not match the received RP1 SYS frame number Error Enable.
  [8] at_ee_rp1_rp3_err — AT PHYT selected width Frame number does not match the received RP1 RP3 frame number Error Enable.
  [7] at_ee_rp1_crc_err — AT RP1 Type CRC Error Enable.
  [6] at_ee_rp1_bit_width_err — AT RP1 Type Bit Width Error Enable.
  [5] at_ee_rp1_type_rsvd_err — AT RP1 Type Reserved Error Enable.
  [4] at_ee_rp1_type_spare_err — AT RP1 Type Spare Error Enable.
  [3] at_ee_rp1_type_unsel_err — AT RP1 Type Unsel Error Enable.
  [2] at_ee_rp1_type_tod_rcvd_err — AT RP1 Type TOD Receive Error Enable.
  [1] at_ee_rp1_type_rp3_rcvd_err — AT RP1 Type RP3 Receive Error Enable.
  [0] at_ee_rp1_type_sys_rcvd_err — AT RP1 Type SYS Receive Error Enable.
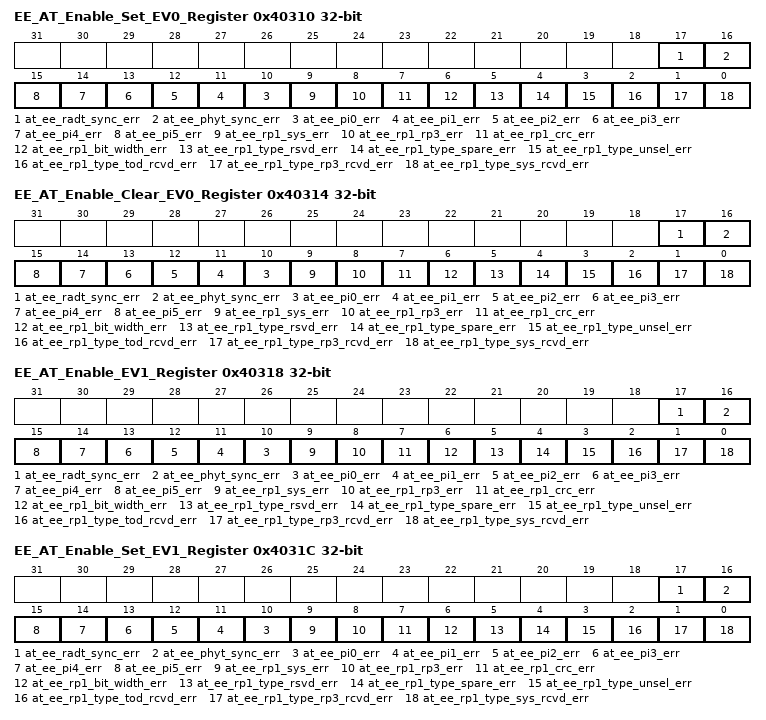
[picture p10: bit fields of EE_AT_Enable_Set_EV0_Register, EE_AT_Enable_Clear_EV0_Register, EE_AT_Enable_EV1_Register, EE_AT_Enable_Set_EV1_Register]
0x40310 EE_AT_Enable_Set_EV0_Register wo
  [17] at_ee_radt_sync_err — AT RADT sync input is not aligned to the RADT counter frame boundary Error Enable Set.
  [16] at_ee_phyt_sync_err — AT PHYT sync input is not aligned to the PHYT counter frame boundary Error Enable Set.
  [n+10] at_ee_pi{n}_err (n=0..5) — AT Link {n} PI Error Enable Set.
  [9] at_ee_rp1_sys_err — AT RADT selected width Frame number does not match the received RP1 SYS frame number Error Enable Set.
  [8] at_ee_rp1_rp3_err — AT PHYT selected width Frame number does not match the received RP1 RP3 frame number Error Enable Set.
  [7] at_ee_rp1_crc_err — AT RP1 Type CRC Error Enable Set.
  [6] at_ee_rp1_bit_width_err — AT RP1 Type Bit Width Error Enable Set.
  [5] at_ee_rp1_type_rsvd_err — AT RP1 Type Reserved Error Enable Set.
  [4] at_ee_rp1_type_spare_err — AT RP1 Type Spare Error Enable Set.
  [3] at_ee_rp1_type_unsel_err — AT RP1 Type Unsel Error Enable Set.
  [2] at_ee_rp1_type_tod_rcvd_err — AT RP1 Type TOD Receive Error Enable Set.
  [1] at_ee_rp1_type_rp3_rcvd_err — AT RP1 Type RP3 Receive Error Enable Set.
  [0] at_ee_rp1_type_sys_rcvd_err — AT RP1 Type SYS Receive Error Enable Set.
0x40314 EE_AT_Enable_Clear_EV0_Register wo
  [17] at_ee_radt_sync_err — AT RADT sync input is not aligned to the RADT counter frame boundary Error Enable Clear.
  [16] at_ee_phyt_sync_err — AT PHYT sync input is not aligned to the PHYT counter frame boundary Error Enable Clear.
  [n+10] at_ee_pi{n}_err (n=0..5) — AT Link {n} PI Error Enable Clear.
  [9] at_ee_rp1_sys_err — AT RADT selected width Frame number does not match the received RP1 SYS frame number Error Enable Clear.
  [8] at_ee_rp1_rp3_err — AT PHYT selected width Frame number does not match the received RP1 RP3 frame number Error Enable Clear.
  [7] at_ee_rp1_crc_err — AT RP1 Type CRC Error Enable Clear.
  [6] at_ee_rp1_bit_width_err — AT RP1 Type Bit Width Error Enable Clear.
  [5] at_ee_rp1_type_rsvd_err — AT RP1 Type Reserved Error.
  [4] at_ee_rp1_type_spare_err — AT RP1 Type Spare Error.
  [3] at_ee_rp1_type_unsel_err — AT RP1 Type Unsel Error Enable Clear.
  [2] at_ee_rp1_type_tod_rcvd_err — AT RP1 Type TOD Receive Error Enable Clear.
  [1] at_ee_rp1_type_rp3_rcvd_err — AT RP1 Type RP3 Receive Error Enable Clear.
  [0] at_ee_rp1_type_sys_rcvd_err — AT RP1 Type SYS Receive Error Enable Clear.
0x40318 EE_AT_Enable_EV1_Register ro
  fields as EE_AT_Enable_EV0_Register
0x4031C EE_AT_Enable_Set_EV1_Register wo
  fields as EE_AT_Enable_Set_EV0_Register
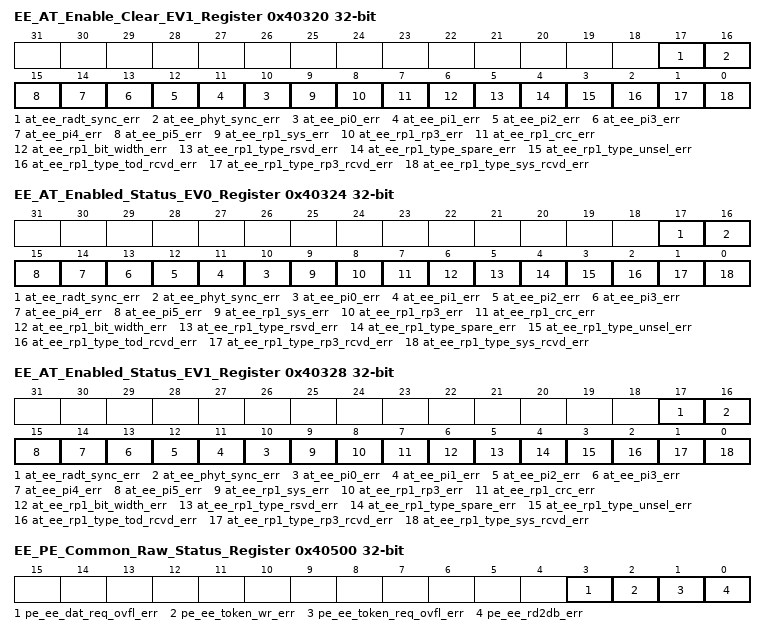
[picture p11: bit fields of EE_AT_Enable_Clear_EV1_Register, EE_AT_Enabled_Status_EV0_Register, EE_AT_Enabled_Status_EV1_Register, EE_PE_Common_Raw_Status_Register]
0x40320 EE_AT_Enable_Clear_EV1_Register wo
  [17] at_ee_radt_sync_err — AT RADT sync input is not aligned to the RADT counter frame boundary Error Enable Clear.
  [16] at_ee_phyt_sync_err — AT PHYT sync input is not aligned to the PHYT counter frame boundary Error Enable Clear.
  [n+10] at_ee_pi{n}_err (n=0..5) — AT Link {n} PI Error Enable Clear.
  [9] at_ee_rp1_sys_err — AT RADT selected width Frame number does not match the received RP1 SYS frame number Error Enable Clear.
  [8] at_ee_rp1_rp3_err — AT PHYT selected width Frame number does not match the received RP1 RP3 frame number Error Enable Clear.
  [7] at_ee_rp1_crc_err — AT RP1 Type CRC Error Enable Clear.
  [6] at_ee_rp1_bit_width_err — AT RP1 Type Bit Width Error Enable Clear.
  [5] at_ee_rp1_type_rsvd_err — AT RP1 Type Reserved Error Enable Clear.
  [4] at_ee_rp1_type_spare_err — AT RP1 Type Spare Error Enable Clear.
  [3] at_ee_rp1_type_unsel_err — AT RP1 Type Unsel Error Enable Clear.
  [2] at_ee_rp1_type_tod_rcvd_err — AT RP1 Type TOD Receive Error Enable Clear.
  [1] at_ee_rp1_type_rp3_rcvd_err — AT RP1 Type RP3 Receive Error Enable Clear.
  [0] at_ee_rp1_type_sys_rcvd_err — AT RP1 Type SYS Receive Error Enable Clear.
0x40324 EE_AT_Enabled_Status_EV0_Register ro
  [17] at_ee_radt_sync_err — AT RADT sync input is not aligned to the RADT counter frame boundary Error Enabled.
  [16] at_ee_phyt_sync_err — AT PHYT sync input is not aligned to the PHYT counter frame boundary Error Enabled.
  [n+10] at_ee_pi{n}_err (n=0..5) — AT Link {n} PI Error Enabled.
  [9] at_ee_rp1_sys_err — AT RADT selected width Frame number does not match the received RP1 SYS frame number Error Enabled.
  [8] at_ee_rp1_rp3_err — AT PHYT selected width Frame number does not match the received RP1 RP3 frame number Error Enabled.
  [7] at_ee_rp1_crc_err — AT RP1 Type CRC Error Enabled.
  [6] at_ee_rp1_bit_width_err — AT RP1 Type Bit Width Error Enabled.
  [5] at_ee_rp1_type_rsvd_err — AT RP1 Type Reserved Error Enabled.
  [4] at_ee_rp1_type_spare_err — AT RP1 Type Spare Error Enabled.
  [3] at_ee_rp1_type_unsel_err — AT RP1 Type Unsel Error Enabled.
  [2] at_ee_rp1_type_tod_rcvd_err — AT RP1 Type TOD Receive Error Enabled.
  [1] at_ee_rp1_type_rp3_rcvd_err — AT RP1 Type RP3 Receive Error Enabled.
  [0] at_ee_rp1_type_sys_rcvd_err — AT RP1 Type SYS Receive Error Enabled.
0x40328 EE_AT_Enabled_Status_EV1_Register ro
  [17] at_ee_radt_sync_err — AT RADT sync input is not aligned to the RADT counter frame boundary Error Enabled.
  [16] at_ee_phyt_sync_err — AT PHYT sync input is not aligned to the PHYT counter frame boundary Error Enabled.
  [n+10] at_ee_pi{n}_err (n=0..5) — AT Link {n} PI Error Enabled.
  [9] at_ee_rp1_sys_err — AT RADT selected width Frame number does not match the received RP1 SYS frame numberd Error Enabled.
  [8] at_ee_rp1_rp3_err — AT PHYT selected width Frame number does not match the received RP1 RP3 frame numberd Error Enabled.
  [7] at_ee_rp1_crc_err — AT RP1 Type CRC Error Enabled.
  [6] at_ee_rp1_bit_width_err — AT RP1 Type Bit Width Error Enabled.
  [5] at_ee_rp1_type_rsvd_err — AT RP1 Type Reserved Error Enabled.
  [4] at_ee_rp1_type_spare_err — AT RP1 Type Spare Error Enabled.
  [3] at_ee_rp1_type_unsel_err — AT RP1 Type Unsel Error Enabled.
  [2] at_ee_rp1_type_tod_rcvd_err — AT RP1 Type TOD Receive Error Enabled.
  [1] at_ee_rp1_type_rp3_rcvd_err — AT RP1 Type RP3 Receive Error Enabled.
  [0] at_ee_rp1_type_sys_rcvd_err — AT RP1 Type SYS Receive Error Enabled.
0x40400 EE_PD_Common_Raw_Status_Register ro
  [0] pd_ee_ts_wdog_err — PD ts watchdog Error.
0x40404 EE_PD_Common_Set_Status_Register wo
  [0] pd_ee_ts_wdog_err — PD ts watchdog Error Set.
0x40408 EE_PD_Common_Clear_Status_Register wo
  [0] pd_ee_ts_wdog_err — PD ts watchdog Error Clear.
0x4040C EE_PD_Common_Enable_EV0_Register ro — EE PD Common Enable EVO Register
  [0] pd_ee_ts_wdog_err — PD ts watchdog Error Enable.
0x40410 EE_PD_Common_Enable_Set_EV0_Register wo
  [0] pd_ee_ts_wdog_err — PD ts watchdog Error Enable Set.
0x40414 EE_PD_Common_Enable_Clear_EV0_Register wo
  [0] pd_ee_ts_wdog_err — PD ts watchdog Error Enable Clear.
0x40418 EE_PD_Common_Enable_EV1_Register ro
  [0] pd_ee_ts_wdog_err — PD ts watchdog Error Enable.
0x4041C EE_PD_Common_Enable_Set_EV1_Register wo
  [0] pd_ee_ts_wdog_err — PD ts watchdog Error Enable Set.
0x40420 EE_PD_Common_Enable_Clear_EV1_Register wo
  [0] pd_ee_ts_wdog_err — PD ts watchdog Error Enable Clear.
0x40424 EE_PD_Common_Enabled_Status_EV0_Register ro
  [0] pd_ee_ts_wdog_err — PD ts watchdog Error Enabled.
0x40428 EE_PD_Common_Enabled_Status_EV1_Register ro
  [0] pd_ee_ts_wdog_err — PD ts watchdog Error Enabled.
0x40500 EE_PE_Common_Raw_Status_Register ro
  [3] pe_ee_dat_req_ovfl_err — PE data register overflow error.
  [2] pe_ee_token_wr_err — PE token write error.
  [1] pe_ee_token_req_ovfl_err — PE token register overflow error.
  [0] pe_ee_rd2db_err — PE read to DB error.
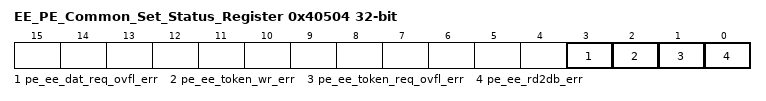
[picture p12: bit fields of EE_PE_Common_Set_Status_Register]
0x40504 EE_PE_Common_Set_Status_Register wo
  [3] pe_ee_dat_req_ovfl_err — PE data register overflow error Set.
  [2] pe_ee_token_wr_err — PE token write error Set.
  [1] pe_ee_token_req_ovfl_err — PE token register overflow error Set.
  [0] pe_ee_rd2db_err — PE read to DB error Set.
